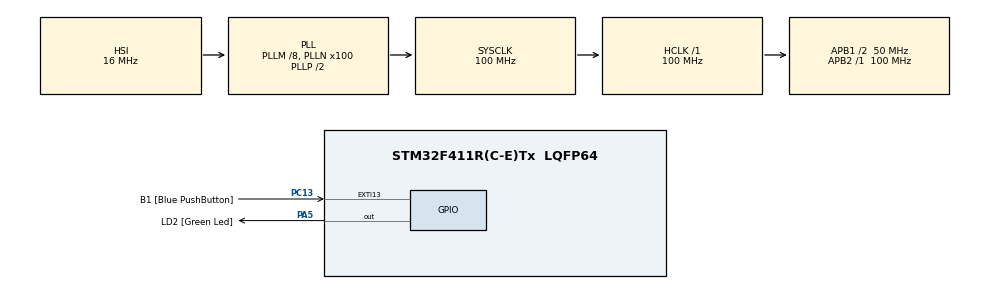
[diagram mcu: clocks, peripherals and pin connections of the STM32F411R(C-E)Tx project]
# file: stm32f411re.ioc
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Mcu.Family=STM32F4
RCC.CortexFreq_Value=100000000
PC13-ANTI_TAMP.GPIO_Label=B1 [Blue PushButton]
PA14.GPIO_Label=TCK
VP_SYS_VS_tim5.Mode=TIM5
RCC.APB1CLKDivider=RCC_HCLK_DIV2
PC14-OSC32_IN.Signal=RCC_OSC32_IN
RCC.SYSCLKSource=RCC_SYSCLKSOURCE_PLLCLK
ProjectManager.StackSize=0x400
PA13.Signal=SYS_JTMS-SWDIO
PH0\ -\ OSC_IN.Signal=RCC_OSC_IN
ProjectManager.TargetToolchain=STM32CubeIDE
NVIC.TIM5_IRQn=true\:0\:0\:false\:false\:true\:false\:true
RCC.HCLKFreq_Value=100000000
RCC.APB2TimFreq_Value=100000000
RCC.LSE_VALUE=32768
PC15-OSC32_OUT.Signal=RCC_OSC32_OUT
RCC.AHBFreq_Value=100000000
PA5.Signal=GPIO_Output
RCC.HSE_VALUE=8000000
PH1\ -\ OSC_OUT.Signal=RCC_OSC_OUT
board=NUCLEO-F411RE
PC13-ANTI_TAMP.Signal=GPXTI13
RCC.VCOOutputFreq_Value=200000000
RCC.APB2Freq_Value=100000000
PA14.Mode=Serial_Wire
PA13.Mode=Serial_Wire
Mcu.Name=STM32F411R(C-E)Tx
PA2.Signal=USART2_TX
PA13.GPIO_Label=TMS
RCC.FLatency-AdvancedSettings=FLASH_LATENCY_3
RCC.48MHZClocksFreq_Value=50000000
PB3.Signal=SYS_JTDO-SWO
RCC.SYSCLKFreq_VALUE=100000000
Mcu.Package=LQFP64
NVIC.TimeBase=TIM5_IRQn
PA5.GPIO_Label=LD2 [Green Led]
PC13-ANTI_TAMP.GPIO_ModeDefaultEXTI=GPIO_MODE_IT_FALLING
PA2.GPIO_Label=USART_TX
NVIC.TimeBaseIP=TIM5
PA14.Signal=SYS_JTCK-SWCLK
ProjectManager.HeapSize=0x200
RCC.HSI_VALUE=16000000
NVIC.PriorityGroup=NVIC_PRIORITYGROUP_0
RCC.PLLM=8
RCC.PLLN=100
RCC.APB1TimFreq_Value=100000000
RCC.APB1Freq_Value=50000000
PA3.GPIO_Label=USART_RX
PA3.Signal=USART2_RX
PB3.GPIO_Label=SWO

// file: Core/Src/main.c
/* USER CODE BEGIN Header */
/**
  ******************************************************************************
  * @file           : main.c
  * @brief          : Main program body
  ******************************************************************************
  * @attention
  *
  * <h2><center>&copy; Copyright (c) 2022 STMicroelectronics.
  * All rights reserved.</center></h2>
  *
  * This software component is licensed by ST under BSD 3-Clause license,
  * the "License"; You may not use this file except in compliance with the
  * License. You may obtain a copy of the License at:
  *                        opensource.org/licenses/BSD-3-Clause
  *
  ******************************************************************************
  */
/* USER CODE END Header */
#include "main.h"
#include "gpio.h"
#include "common.h"

extern int main_user();
/* USER CODE BEGIN Includes */
/* This is a small demo of the high-performance ThreadX kernel.  It includes examples of eight
   threads of different priorities, using a message queue, semaphore, mutex, event flags group,
   byte pool, and block pool.  */

/* USER CODE END Includes */

void SystemClock_Config(void);

int main(void)
{

  /* MCU Configuration--------------------------------------------------------*/

  /* Reset of all peripherals, Initializes the Flash interface and the Systick. */
  HAL_Init();

  /* Configure the system clock */
  SystemClock_Config();

  /* Initialize all configured peripherals */
  MX_GPIO_Init();

  /* Infinite loop */
  /* USER CODE BEGIN WHILE */

      /* Enter the ThreadX kernel. */
  main_user();

  while (1)
  {

    /* USER CODE END WHILE */

  }
}

void SystemClock_Config(void)
{
  RCC_OscInitTypeDef RCC_OscInitStruct = {0};
  RCC_ClkInitTypeDef RCC_ClkInitStruct = {0};

  /** Configure the main internal regulator output voltage
  */
  __HAL_RCC_PWR_CLK_ENABLE();
  __HAL_PWR_VOLTAGESCALING_CONFIG(PWR_REGULATOR_VOLTAGE_SCALE1);
  /** Initializes the RCC Oscillators according to the specified parameters
  * in the RCC_OscInitTypeDef structure.
  */
  RCC_OscInitStruct.OscillatorType = RCC_OSCILLATORTYPE_HSI;
  RCC_OscInitStruct.HSIState = RCC_HSI_ON;
  RCC_OscInitStruct.HSICalibrationValue = RCC_HSICALIBRATION_DEFAULT;
  RCC_OscInitStruct.PLL.PLLState = RCC_PLL_ON;
  RCC_OscInitStruct.PLL.PLLSource = RCC_PLLSOURCE_HSI;
  RCC_OscInitStruct.PLL.PLLM = 8;
  RCC_OscInitStruct.PLL.PLLN = 100;
  RCC_OscInitStruct.PLL.PLLP = RCC_PLLP_DIV2;
  RCC_OscInitStruct.PLL.PLLQ = 4;
  if (HAL_RCC_OscConfig(&RCC_OscInitStruct) != HAL_OK)
  {
    Error_Handler();
  }
  /** Initializes the CPU, AHB and APB buses clocks
  */
  RCC_ClkInitStruct.ClockType = RCC_CLOCKTYPE_HCLK|RCC_CLOCKTYPE_SYSCLK
                              |RCC_CLOCKTYPE_PCLK1|RCC_CLOCKTYPE_PCLK2;
  RCC_ClkInitStruct.SYSCLKSource = RCC_SYSCLKSOURCE_PLLCLK;
  RCC_ClkInitStruct.AHBCLKDivider = RCC_SYSCLK_DIV1;
  RCC_ClkInitStruct.APB1CLKDivider = RCC_HCLK_DIV2;
  RCC_ClkInitStruct.APB2CLKDivider = RCC_HCLK_DIV1;

  if (HAL_RCC_ClockConfig(&RCC_ClkInitStruct, FLASH_LATENCY_3) != HAL_OK)
  {
    Error_Handler();
  }
}

 /**
  * @brief  Period elapsed callback in non blocking mode
  * @note   This function is called  when TIM5 interrupt took place, inside
  * HAL_TIM_IRQHandler(). It makes a direct call to HAL_IncTick() to increment
  * a global variable "uwTick" used as application time base.
  * @param  htim : TIM handle
  * @retval None
  */
void HAL_TIM_PeriodElapsedCallback(TIM_HandleTypeDef *htim)
{
  if (htim->Instance == TIM5) {
    HAL_IncTick();
  }
}

void Error_Handler(void)
{
  __disable_irq();
  while (1)
  {
  }
}

/************************ (C) COPYRIGHT STMicroelectronics *****END OF FILE****/
